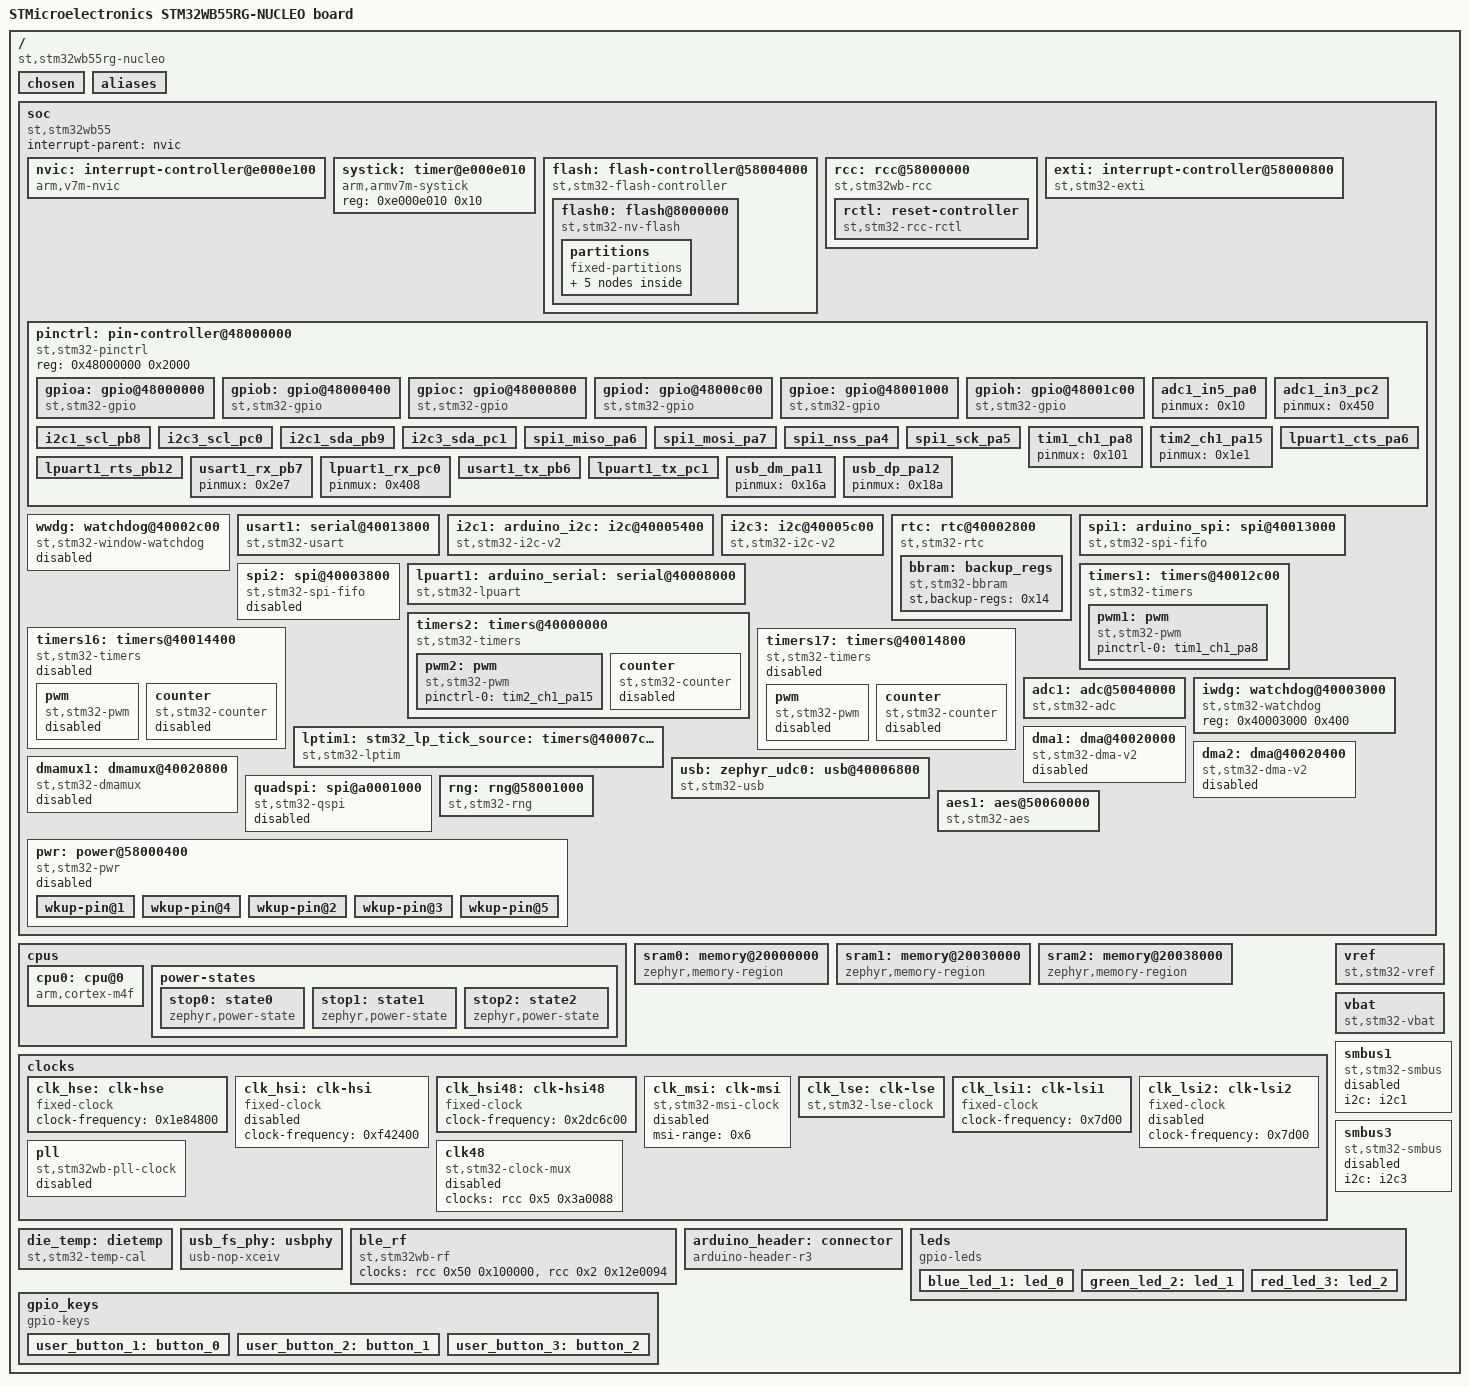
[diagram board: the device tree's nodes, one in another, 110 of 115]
/dts-v1/;

/* node '/' defined in zephyr/dts/common/skeleton.dtsi:9 */
/ {
	#address-cells = < 0x1 >;                              /* in zephyr/dts/common/skeleton.dtsi:10 */
	#size-cells = < 0x1 >;                                 /* in zephyr/dts/common/skeleton.dtsi:11 */
	model = "STMicroelectronics STM32WB55RG-NUCLEO board"; /* in zephyr/boards/st/nucleo_wb55rg/nucleo_wb55rg.dts:14 */
	compatible = "st,stm32wb55rg-nucleo";                  /* in zephyr/boards/st/nucleo_wb55rg/nucleo_wb55rg.dts:15 */

	/* node '/chosen' defined in zephyr/dts/common/skeleton.dtsi:13 */
	chosen {
		zephyr,entropy = &rng;                    /* in zephyr/dts/arm/st/wb/stm32wb.dtsi:25 */
		zephyr,flash-controller = &flash;         /* in zephyr/dts/arm/st/wb/stm32wb.dtsi:26 */
		zephyr,bt-hci = &ble_rf;                  /* in zephyr/dts/arm/st/wb/stm32wb.dtsi:27 */
		zephyr,console = &usart1;                 /* in zephyr/boards/st/nucleo_wb55rg/nucleo_wb55rg.dts:18 */
		zephyr,shell-uart = &usart1;              /* in zephyr/boards/st/nucleo_wb55rg/nucleo_wb55rg.dts:19 */
		zephyr,bt-mon-uart = &lpuart1;            /* in zephyr/boards/st/nucleo_wb55rg/nucleo_wb55rg.dts:20 */
		zephyr,bt-c2h-uart = &lpuart1;            /* in zephyr/boards/st/nucleo_wb55rg/nucleo_wb55rg.dts:21 */
		zephyr,sram = &sram0;                     /* in zephyr/boards/st/nucleo_wb55rg/nucleo_wb55rg.dts:22 */
		zephyr,flash = &flash0;                   /* in zephyr/boards/st/nucleo_wb55rg/nucleo_wb55rg.dts:23 */
		zephyr,code-partition = &slot0_partition; /* in zephyr/boards/st/nucleo_wb55rg/nucleo_wb55rg.dts:24 */
	};

	/* node '/aliases' defined in zephyr/dts/common/skeleton.dtsi:15 */
	aliases {
		led0 = &blue_led_1;               /* in zephyr/boards/st/nucleo_wb55rg/nucleo_wb55rg.dts:69 */
		led1 = &green_led_2;              /* in zephyr/boards/st/nucleo_wb55rg/nucleo_wb55rg.dts:70 */
		led2 = &red_led_3;                /* in zephyr/boards/st/nucleo_wb55rg/nucleo_wb55rg.dts:71 */
		sw0 = &user_button_1;             /* in zephyr/boards/st/nucleo_wb55rg/nucleo_wb55rg.dts:72 */
		sw1 = &user_button_2;             /* in zephyr/boards/st/nucleo_wb55rg/nucleo_wb55rg.dts:73 */
		sw2 = &user_button_3;             /* in zephyr/boards/st/nucleo_wb55rg/nucleo_wb55rg.dts:74 */
		watchdog0 = &iwdg;                /* in zephyr/boards/st/nucleo_wb55rg/nucleo_wb55rg.dts:75 */
		die-temp0 = &die_temp;            /* in zephyr/boards/st/nucleo_wb55rg/nucleo_wb55rg.dts:76 */
		volt-sensor0 = &vref;             /* in zephyr/boards/st/nucleo_wb55rg/nucleo_wb55rg.dts:77 */
		volt-sensor1 = &vbat;             /* in zephyr/boards/st/nucleo_wb55rg/nucleo_wb55rg.dts:78 */
		mcuboot-led0 = &blue_led_1;       /* in zephyr/boards/st/nucleo_wb55rg/nucleo_wb55rg.dts:79 */
		mcuboot-button0 = &user_button_1; /* in zephyr/boards/st/nucleo_wb55rg/nucleo_wb55rg.dts:80 */
	};

	/* node '/soc' defined in zephyr/dts/arm/armv7-m.dtsi:6 */
	soc {
		#address-cells = < 0x1 >;     /* in zephyr/dts/arm/armv7-m.dtsi:7 */
		#size-cells = < 0x1 >;        /* in zephyr/dts/arm/armv7-m.dtsi:8 */
		interrupt-parent = < &nvic >; /* in zephyr/dts/arm/armv7-m.dtsi:10 */
		ranges;                       /* in zephyr/dts/arm/armv7-m.dtsi:11 */
		compatible = "st,stm32wb55",
		             "st,stm32wb",
		             "simple-bus";    /* in zephyr/dts/arm/st/wb/stm32wb55.dtsi:11 */

		/* node '/soc/interrupt-controller@e000e100' defined in zephyr/dts/arm/armv7-m.dtsi:13 */
		nvic: interrupt-controller@e000e100 {
			#address-cells = < 0x1 >;            /* in zephyr/dts/arm/armv7-m.dtsi:14 */
			compatible = "arm,v7m-nvic";         /* in zephyr/dts/arm/armv7-m.dtsi:15 */
			reg = < 0xe000e100 0xc00 >;          /* in zephyr/dts/arm/armv7-m.dtsi:16 */
			interrupt-controller;                /* in zephyr/dts/arm/armv7-m.dtsi:17 */
			#interrupt-cells = < 0x2 >;          /* in zephyr/dts/arm/armv7-m.dtsi:18 */
			arm,num-irq-priority-bits = < 0x4 >; /* in zephyr/dts/arm/st/wb/stm32wb.dtsi:615 */
			phandle = < 0x1 >;                   /* in zephyr/dts/arm/armv7-m.dtsi:10 */
		};

		/* node '/soc/timer@e000e010' defined in zephyr/dts/arm/armv7-m.dtsi:21 */
		systick: timer@e000e010 {
			compatible = "arm,armv7m-systick"; /* in zephyr/dts/arm/armv7-m.dtsi:22 */
			reg = < 0xe000e010 0x10 >;         /* in zephyr/dts/arm/armv7-m.dtsi:23 */
		};

		/* node '/soc/flash-controller@58004000' defined in zephyr/dts/arm/st/wb/stm32wb.dtsi:148 */
		flash: flash-controller@58004000 {
			compatible = "st,stm32-flash-controller",
			             "st,stm32wb-flash-controller"; /* in zephyr/dts/arm/st/wb/stm32wb.dtsi:149 */
			reg = < 0x58004000 0x400 >;                 /* in zephyr/dts/arm/st/wb/stm32wb.dtsi:150 */
			interrupts = < 0x4 0x0 >;                   /* in zephyr/dts/arm/st/wb/stm32wb.dtsi:151 */
			clocks = < &rcc 0x50 0x2000000 >;           /* in zephyr/dts/arm/st/wb/stm32wb.dtsi:152 */
			#address-cells = < 0x1 >;                   /* in zephyr/dts/arm/st/wb/stm32wb.dtsi:154 */
			#size-cells = < 0x1 >;                      /* in zephyr/dts/arm/st/wb/stm32wb.dtsi:155 */

			/* node '/soc/flash-controller@58004000/flash@8000000' defined in zephyr/dts/arm/st/wb/stm32wb.dtsi:157 */
			flash0: flash@8000000 {
				compatible = "st,stm32-nv-flash",
				             "soc-nv-flash";      /* in zephyr/dts/arm/st/wb/stm32wb.dtsi:158 */
				write-block-size = < 0x8 >;       /* in zephyr/dts/arm/st/wb/stm32wb.dtsi:160 */
				erase-block-size = < 0x1000 >;    /* in zephyr/dts/arm/st/wb/stm32wb.dtsi:161 */
				max-erase-time = < 0x19 >;        /* in zephyr/dts/arm/st/wb/stm32wb.dtsi:163 */
				reg = < 0x8000000 0xca000 >;      /* in zephyr/dts/arm/st/wb/stm32wb55Xg.dtsi:17 */

				/* node '/soc/flash-controller@58004000/flash@8000000/partitions' defined in zephyr/boards/st/nucleo_wb55rg/nucleo_wb55rg.dts:221 */
				partitions {
					compatible = "fixed-partitions"; /* in zephyr/boards/st/nucleo_wb55rg/nucleo_wb55rg.dts:222 */
					#address-cells = < 0x1 >;        /* in zephyr/boards/st/nucleo_wb55rg/nucleo_wb55rg.dts:223 */
					#size-cells = < 0x1 >;           /* in zephyr/boards/st/nucleo_wb55rg/nucleo_wb55rg.dts:224 */

					/* node '/soc/flash-controller@58004000/flash@8000000/partitions/partition@0' defined in zephyr/boards/st/nucleo_wb55rg/nucleo_wb55rg.dts:233 */
					boot_partition: partition@0 {
						label = "mcuboot";    /* in zephyr/boards/st/nucleo_wb55rg/nucleo_wb55rg.dts:234 */
						reg = < 0x0 0xc000 >; /* in zephyr/boards/st/nucleo_wb55rg/nucleo_wb55rg.dts:235 */
					};

					/* node '/soc/flash-controller@58004000/flash@8000000/partitions/partition@c000' defined in zephyr/boards/st/nucleo_wb55rg/nucleo_wb55rg.dts:238 */
					slot0_partition: partition@c000 {
						label = "image-0";        /* in zephyr/boards/st/nucleo_wb55rg/nucleo_wb55rg.dts:239 */
						reg = < 0xc000 0x64000 >; /* in zephyr/boards/st/nucleo_wb55rg/nucleo_wb55rg.dts:240 */
					};

					/* node '/soc/flash-controller@58004000/flash@8000000/partitions/partition@70000' defined in zephyr/boards/st/nucleo_wb55rg/nucleo_wb55rg.dts:243 */
					slot1_partition: partition@70000 {
						label = "image-1";         /* in zephyr/boards/st/nucleo_wb55rg/nucleo_wb55rg.dts:244 */
						reg = < 0x70000 0x64000 >; /* in zephyr/boards/st/nucleo_wb55rg/nucleo_wb55rg.dts:245 */
					};

					/* node '/soc/flash-controller@58004000/flash@8000000/partitions/partition@d4000' defined in zephyr/boards/st/nucleo_wb55rg/nucleo_wb55rg.dts:248 */
					scratch_partition: partition@d4000 {
						label = "image-scratch";  /* in zephyr/boards/st/nucleo_wb55rg/nucleo_wb55rg.dts:249 */
						reg = < 0xd4000 0x4000 >; /* in zephyr/boards/st/nucleo_wb55rg/nucleo_wb55rg.dts:250 */
					};

					/* node '/soc/flash-controller@58004000/flash@8000000/partitions/partition@d8000' defined in zephyr/boards/st/nucleo_wb55rg/nucleo_wb55rg.dts:253 */
					storage_partition: partition@d8000 {
						label = "storage";        /* in zephyr/boards/st/nucleo_wb55rg/nucleo_wb55rg.dts:254 */
						reg = < 0xd8000 0x2000 >; /* in zephyr/boards/st/nucleo_wb55rg/nucleo_wb55rg.dts:255 */
					};
				};
			};
		};

		/* node '/soc/rcc@58000000' defined in zephyr/dts/arm/st/wb/stm32wb.dtsi:167 */
		rcc: rcc@58000000 {
			compatible = "st,stm32wb-rcc";   /* in zephyr/dts/arm/st/wb/stm32wb.dtsi:168 */
			#clock-cells = < 0x2 >;          /* in zephyr/dts/arm/st/wb/stm32wb.dtsi:169 */
			reg = < 0x58000000 0x400 >;      /* in zephyr/dts/arm/st/wb/stm32wb.dtsi:170 */
			clocks = < &clk_hse >;           /* in zephyr/boards/st/nucleo_wb55rg/nucleo_wb55rg.dts:111 */
			clock-frequency = < 0x1e84800 >; /* in zephyr/boards/st/nucleo_wb55rg/nucleo_wb55rg.dts:112 */
			cpu1-prescaler = < 0x1 >;        /* in zephyr/boards/st/nucleo_wb55rg/nucleo_wb55rg.dts:113 */
			cpu2-prescaler = < 0x1 >;        /* in zephyr/boards/st/nucleo_wb55rg/nucleo_wb55rg.dts:114 */
			ahb4-prescaler = < 0x1 >;        /* in zephyr/boards/st/nucleo_wb55rg/nucleo_wb55rg.dts:115 */
			apb1-prescaler = < 0x1 >;        /* in zephyr/boards/st/nucleo_wb55rg/nucleo_wb55rg.dts:116 */
			apb2-prescaler = < 0x1 >;        /* in zephyr/boards/st/nucleo_wb55rg/nucleo_wb55rg.dts:117 */
			phandle = < 0x2 >;               /* in zephyr/dts/arm/st/wb/stm32wb.dtsi:152 */

			/* node '/soc/rcc@58000000/reset-controller' defined in zephyr/dts/arm/st/wb/stm32wb.dtsi:172 */
			rctl: reset-controller {
				compatible = "st,stm32-rcc-rctl"; /* in zephyr/dts/arm/st/wb/stm32wb.dtsi:173 */
				#reset-cells = < 0x1 >;           /* in zephyr/dts/arm/st/wb/stm32wb.dtsi:174 */
				phandle = < 0x4 >;                /* in zephyr/dts/arm/st/wb/stm32wb.dtsi:262 */
			};
		};

		/* node '/soc/interrupt-controller@58000800' defined in zephyr/dts/arm/st/wb/stm32wb.dtsi:178 */
		exti: interrupt-controller@58000800 {
			compatible = "st,stm32-exti";  /* in zephyr/dts/arm/st/wb/stm32wb.dtsi:179 */
			interrupt-controller;          /* in zephyr/dts/arm/st/wb/stm32wb.dtsi:180 */
			#interrupt-cells = < 0x1 >;    /* in zephyr/dts/arm/st/wb/stm32wb.dtsi:181 */
			#address-cells = < 0x0 >;      /* in zephyr/dts/arm/st/wb/stm32wb.dtsi:182 */
			reg = < 0x58000800 0x400 >;    /* in zephyr/dts/arm/st/wb/stm32wb.dtsi:183 */
			num-lines = < 0x40 >;          /* in zephyr/dts/arm/st/wb/stm32wb.dtsi:184 */
			interrupts = < 0x6 0x0 >,
			             < 0x7 0x0 >,
			             < 0x8 0x0 >,
			             < 0x9 0x0 >,
			             < 0xa 0x0 >,
			             < 0x17 0x0 >,
			             < 0x28 0x0 >;     /* in zephyr/dts/arm/st/wb/stm32wb.dtsi:185 */
			interrupt-names = "line0",
			                  "line1",
			                  "line2",
			                  "line3",
			                  "line4",
			                  "line5-9",
			                  "line10-15"; /* in zephyr/dts/arm/st/wb/stm32wb.dtsi:187 */
			line-ranges = < 0x0 0x1 >,
			              < 0x1 0x1 >,
			              < 0x2 0x1 >,
			              < 0x3 0x1 >,
			              < 0x4 0x1 >,
			              < 0x5 0x5 >,
			              < 0xa 0x6 >;     /* in zephyr/dts/arm/st/wb/stm32wb.dtsi:189 */
		};

		/* node '/soc/pin-controller@48000000' defined in zephyr/dts/arm/st/wb/stm32wb.dtsi:193 */
		pinctrl: pin-controller@48000000 {
			compatible = "st,stm32-pinctrl"; /* in zephyr/dts/arm/st/wb/stm32wb.dtsi:194 */
			#address-cells = < 0x1 >;        /* in zephyr/dts/arm/st/wb/stm32wb.dtsi:195 */
			#size-cells = < 0x1 >;           /* in zephyr/dts/arm/st/wb/stm32wb.dtsi:196 */
			reg = < 0x48000000 0x2000 >;     /* in zephyr/dts/arm/st/wb/stm32wb.dtsi:197 */

			/* node '/soc/pin-controller@48000000/gpio@48000000' defined in zephyr/dts/arm/st/wb/stm32wb.dtsi:199 */
			gpioa: gpio@48000000 {
				compatible = "st,stm32-gpio"; /* in zephyr/dts/arm/st/wb/stm32wb.dtsi:200 */
				gpio-controller;              /* in zephyr/dts/arm/st/wb/stm32wb.dtsi:201 */
				#gpio-cells = < 0x2 >;        /* in zephyr/dts/arm/st/wb/stm32wb.dtsi:202 */
				reg = < 0x48000000 0x400 >;   /* in zephyr/dts/arm/st/wb/stm32wb.dtsi:203 */
				clocks = < &rcc 0x4c 0x1 >;   /* in zephyr/dts/arm/st/wb/stm32wb.dtsi:204 */
				phandle = < 0x1a >;           /* in zephyr/dts/arm/st/wb/stm32wb.dtsi:550 */
			};

			/* node '/soc/pin-controller@48000000/gpio@48000400' defined in zephyr/dts/arm/st/wb/stm32wb.dtsi:207 */
			gpiob: gpio@48000400 {
				compatible = "st,stm32-gpio"; /* in zephyr/dts/arm/st/wb/stm32wb.dtsi:208 */
				gpio-controller;              /* in zephyr/dts/arm/st/wb/stm32wb.dtsi:209 */
				#gpio-cells = < 0x2 >;        /* in zephyr/dts/arm/st/wb/stm32wb.dtsi:210 */
				reg = < 0x48000400 0x400 >;   /* in zephyr/dts/arm/st/wb/stm32wb.dtsi:211 */
				clocks = < &rcc 0x4c 0x2 >;   /* in zephyr/dts/arm/st/wb/stm32wb.dtsi:212 */
				phandle = < 0x22 >;           /* in zephyr/boards/st/nucleo_wb55rg/arduino_r3_connector.dtsi:15 */
			};

			/* node '/soc/pin-controller@48000000/gpio@48000800' defined in zephyr/dts/arm/st/wb/stm32wb.dtsi:215 */
			gpioc: gpio@48000800 {
				compatible = "st,stm32-gpio"; /* in zephyr/dts/arm/st/wb/stm32wb.dtsi:216 */
				gpio-controller;              /* in zephyr/dts/arm/st/wb/stm32wb.dtsi:217 */
				#gpio-cells = < 0x2 >;        /* in zephyr/dts/arm/st/wb/stm32wb.dtsi:218 */
				reg = < 0x48000800 0x400 >;   /* in zephyr/dts/arm/st/wb/stm32wb.dtsi:219 */
				clocks = < &rcc 0x4c 0x4 >;   /* in zephyr/dts/arm/st/wb/stm32wb.dtsi:220 */
				phandle = < 0x1b >;           /* in zephyr/dts/arm/st/wb/stm32wb55Xg.dtsi:26 */
			};

			/* node '/soc/pin-controller@48000000/gpio@48000c00' defined in zephyr/dts/arm/st/wb/stm32wb.dtsi:223 */
			gpiod: gpio@48000c00 {
				compatible = "st,stm32-gpio"; /* in zephyr/dts/arm/st/wb/stm32wb.dtsi:224 */
				gpio-controller;              /* in zephyr/dts/arm/st/wb/stm32wb.dtsi:225 */
				#gpio-cells = < 0x2 >;        /* in zephyr/dts/arm/st/wb/stm32wb.dtsi:226 */
				reg = < 0x48000c00 0x400 >;   /* in zephyr/dts/arm/st/wb/stm32wb.dtsi:227 */
				clocks = < &rcc 0x4c 0x8 >;   /* in zephyr/dts/arm/st/wb/stm32wb.dtsi:228 */
				phandle = < 0x23 >;           /* in zephyr/boards/st/nucleo_wb55rg/nucleo_wb55rg.dts:57 */
			};

			/* node '/soc/pin-controller@48000000/gpio@48001000' defined in zephyr/dts/arm/st/wb/stm32wb.dtsi:231 */
			gpioe: gpio@48001000 {
				compatible = "st,stm32-gpio"; /* in zephyr/dts/arm/st/wb/stm32wb.dtsi:232 */
				gpio-controller;              /* in zephyr/dts/arm/st/wb/stm32wb.dtsi:233 */
				#gpio-cells = < 0x2 >;        /* in zephyr/dts/arm/st/wb/stm32wb.dtsi:234 */
				ngpios = < 0x5 >;             /* in zephyr/dts/arm/st/wb/stm32wb.dtsi:235 */
				reg = < 0x48001000 0x400 >;   /* in zephyr/dts/arm/st/wb/stm32wb.dtsi:236 */
				clocks = < &rcc 0x4c 0x10 >;  /* in zephyr/dts/arm/st/wb/stm32wb.dtsi:237 */
			};

			/* node '/soc/pin-controller@48000000/gpio@48001c00' defined in zephyr/dts/arm/st/wb/stm32wb.dtsi:240 */
			gpioh: gpio@48001c00 {
				compatible = "st,stm32-gpio"; /* in zephyr/dts/arm/st/wb/stm32wb.dtsi:241 */
				gpio-controller;              /* in zephyr/dts/arm/st/wb/stm32wb.dtsi:242 */
				#gpio-cells = < 0x2 >;        /* in zephyr/dts/arm/st/wb/stm32wb.dtsi:243 */
				ngpios = < 0x4 >;             /* in zephyr/dts/arm/st/wb/stm32wb.dtsi:244 */
				reg = < 0x48001c00 0x400 >;   /* in zephyr/dts/arm/st/wb/stm32wb.dtsi:245 */
				clocks = < &rcc 0x4c 0x80 >;  /* in zephyr/dts/arm/st/wb/stm32wb.dtsi:246 */
			};

			/* node '/soc/pin-controller@48000000/adc1_in5_pa0' defined in modules/hal/stm32/dts/st/wb/stm32wb55rgvx-pinctrl.dtsi:15 */
			adc1_in5_pa0: adc1_in5_pa0 {
				pinmux = < 0x10 >;  /* in modules/hal/stm32/dts/st/wb/stm32wb55rgvx-pinctrl.dtsi:16 */
				phandle = < 0x16 >; /* in zephyr/boards/st/nucleo_wb55rg/nucleo_wb55rg.dts:189 */
			};

			/* node '/soc/pin-controller@48000000/adc1_in3_pc2' defined in modules/hal/stm32/dts/st/wb/stm32wb55rgvx-pinctrl.dtsi:63 */
			adc1_in3_pc2: adc1_in3_pc2 {
				pinmux = < 0x450 >; /* in modules/hal/stm32/dts/st/wb/stm32wb55rgvx-pinctrl.dtsi:64 */
				phandle = < 0x15 >; /* in zephyr/boards/st/nucleo_wb55rg/nucleo_wb55rg.dts:189 */
			};

			/* node '/soc/pin-controller@48000000/i2c1_scl_pb8' defined in modules/hal/stm32/dts/st/wb/stm32wb55rgvx-pinctrl.dtsi:387 */
			i2c1_scl_pb8: i2c1_scl_pb8 {
				pinmux = < 0x304 >; /* in modules/hal/stm32/dts/st/wb/stm32wb55rgvx-pinctrl.dtsi:388 */
				bias-pull-up;       /* in modules/hal/stm32/dts/st/wb/stm32wb55rgvx-pinctrl.dtsi:389 */
				drive-open-drain;   /* in modules/hal/stm32/dts/st/wb/stm32wb55rgvx-pinctrl.dtsi:390 */
				phandle = < 0x7 >;  /* in zephyr/boards/st/nucleo_wb55rg/nucleo_wb55rg.dts:128 */
			};

			/* node '/soc/pin-controller@48000000/i2c3_scl_pc0' defined in modules/hal/stm32/dts/st/wb/stm32wb55rgvx-pinctrl.dtsi:411 */
			i2c3_scl_pc0: i2c3_scl_pc0 {
				pinmux = < 0x404 >; /* in modules/hal/stm32/dts/st/wb/stm32wb55rgvx-pinctrl.dtsi:412 */
				bias-pull-up;       /* in modules/hal/stm32/dts/st/wb/stm32wb55rgvx-pinctrl.dtsi:413 */
				drive-open-drain;   /* in modules/hal/stm32/dts/st/wb/stm32wb55rgvx-pinctrl.dtsi:414 */
				phandle = < 0x9 >;  /* in zephyr/boards/st/nucleo_wb55rg/nucleo_wb55rg.dts:135 */
			};

			/* node '/soc/pin-controller@48000000/i2c1_sda_pb9' defined in modules/hal/stm32/dts/st/wb/stm32wb55rgvx-pinctrl.dtsi:431 */
			i2c1_sda_pb9: i2c1_sda_pb9 {
				pinmux = < 0x324 >; /* in modules/hal/stm32/dts/st/wb/stm32wb55rgvx-pinctrl.dtsi:432 */
				bias-pull-up;       /* in modules/hal/stm32/dts/st/wb/stm32wb55rgvx-pinctrl.dtsi:433 */
				drive-open-drain;   /* in modules/hal/stm32/dts/st/wb/stm32wb55rgvx-pinctrl.dtsi:434 */
				phandle = < 0x8 >;  /* in zephyr/boards/st/nucleo_wb55rg/nucleo_wb55rg.dts:128 */
			};

			/* node '/soc/pin-controller@48000000/i2c3_sda_pc1' defined in modules/hal/stm32/dts/st/wb/stm32wb55rgvx-pinctrl.dtsi:455 */
			i2c3_sda_pc1: i2c3_sda_pc1 {
				pinmux = < 0x424 >; /* in modules/hal/stm32/dts/st/wb/stm32wb55rgvx-pinctrl.dtsi:456 */
				bias-pull-up;       /* in modules/hal/stm32/dts/st/wb/stm32wb55rgvx-pinctrl.dtsi:457 */
				drive-open-drain;   /* in modules/hal/stm32/dts/st/wb/stm32wb55rgvx-pinctrl.dtsi:458 */
				phandle = < 0xa >;  /* in zephyr/boards/st/nucleo_wb55rg/nucleo_wb55rg.dts:135 */
			};

			/* node '/soc/pin-controller@48000000/spi1_miso_pa6' defined in modules/hal/stm32/dts/st/wb/stm32wb55rgvx-pinctrl.dtsi:693 */
			spi1_miso_pa6: spi1_miso_pa6 {
				pinmux = < 0xc5 >; /* in modules/hal/stm32/dts/st/wb/stm32wb55rgvx-pinctrl.dtsi:694 */
				bias-pull-down;    /* in modules/hal/stm32/dts/st/wb/stm32wb55rgvx-pinctrl.dtsi:695 */
				phandle = < 0xd >; /* in zephyr/boards/st/nucleo_wb55rg/nucleo_wb55rg.dts:152 */
			};

			/* node '/soc/pin-controller@48000000/spi1_mosi_pa7' defined in modules/hal/stm32/dts/st/wb/stm32wb55rgvx-pinctrl.dtsi:720 */
			spi1_mosi_pa7: spi1_mosi_pa7 {
				pinmux = < 0xe5 >; /* in modules/hal/stm32/dts/st/wb/stm32wb55rgvx-pinctrl.dtsi:721 */
				bias-pull-down;    /* in modules/hal/stm32/dts/st/wb/stm32wb55rgvx-pinctrl.dtsi:722 */
				phandle = < 0xe >; /* in zephyr/boards/st/nucleo_wb55rg/nucleo_wb55rg.dts:152 */
			};

			/* node '/soc/pin-controller@48000000/spi1_nss_pa4' defined in modules/hal/stm32/dts/st/wb/stm32wb55rgvx-pinctrl.dtsi:752 */
			spi1_nss_pa4: spi1_nss_pa4 {
				pinmux = < 0x85 >; /* in modules/hal/stm32/dts/st/wb/stm32wb55rgvx-pinctrl.dtsi:753 */
				bias-pull-up;      /* in modules/hal/stm32/dts/st/wb/stm32wb55rgvx-pinctrl.dtsi:754 */
				phandle = < 0xb >; /* in zephyr/boards/st/nucleo_wb55rg/nucleo_wb55rg.dts:152 */
			};

			/* node '/soc/pin-controller@48000000/spi1_sck_pa5' defined in modules/hal/stm32/dts/st/wb/stm32wb55rgvx-pinctrl.dtsi:790 */
			spi1_sck_pa5: spi1_sck_pa5 {
				pinmux = < 0xa5 >;             /* in modules/hal/stm32/dts/st/wb/stm32wb55rgvx-pinctrl.dtsi:791 */
				bias-pull-down;                /* in modules/hal/stm32/dts/st/wb/stm32wb55rgvx-pinctrl.dtsi:792 */
				slew-rate = "very-high-speed"; /* in modules/hal/stm32/dts/st/wb/stm32wb55rgvx-pinctrl.dtsi:793 */
				phandle = < 0xc >;             /* in zephyr/boards/st/nucleo_wb55rg/nucleo_wb55rg.dts:152 */
			};

			/* node '/soc/pin-controller@48000000/tim1_ch1_pa8' defined in modules/hal/stm32/dts/st/wb/stm32wb55rgvx-pinctrl.dtsi:862 */
			tim1_ch1_pa8: tim1_ch1_pa8 {
				pinmux = < 0x101 >; /* in modules/hal/stm32/dts/st/wb/stm32wb55rgvx-pinctrl.dtsi:863 */
				phandle = < 0x13 >; /* in zephyr/boards/st/nucleo_wb55rg/nucleo_wb55rg.dts:164 */
			};

			/* node '/soc/pin-controller@48000000/tim2_ch1_pa15' defined in modules/hal/stm32/dts/st/wb/stm32wb55rgvx-pinctrl.dtsi:918 */
			tim2_ch1_pa15: tim2_ch1_pa15 {
				pinmux = < 0x1e1 >; /* in modules/hal/stm32/dts/st/wb/stm32wb55rgvx-pinctrl.dtsi:919 */
				phandle = < 0x14 >; /* in zephyr/boards/st/nucleo_wb55rg/nucleo_wb55rg.dts:174 */
			};

			/* node '/soc/pin-controller@48000000/lpuart1_cts_pa6' defined in modules/hal/stm32/dts/st/wb/stm32wb55rgvx-pinctrl.dtsi:1014 */
			lpuart1_cts_pa6: lpuart1_cts_pa6 {
				pinmux = < 0xc8 >;  /* in modules/hal/stm32/dts/st/wb/stm32wb55rgvx-pinctrl.dtsi:1015 */
				bias-pull-up;       /* in modules/hal/stm32/dts/st/wb/stm32wb55rgvx-pinctrl.dtsi:1016 */
				phandle = < 0x11 >; /* in zephyr/boards/st/nucleo_wb55rg/nucleo_wb55rg.dts:180 */
			};

			/* node '/soc/pin-controller@48000000/lpuart1_rts_pb12' defined in modules/hal/stm32/dts/st/wb/stm32wb55rgvx-pinctrl.dtsi:1073 */
			lpuart1_rts_pb12: lpuart1_rts_pb12 {
				pinmux = < 0x388 >; /* in modules/hal/stm32/dts/st/wb/stm32wb55rgvx-pinctrl.dtsi:1074 */
				drive-push-pull;    /* in modules/hal/stm32/dts/st/wb/stm32wb55rgvx-pinctrl.dtsi:1075 */
				phandle = < 0x12 >; /* in zephyr/boards/st/nucleo_wb55rg/nucleo_wb55rg.dts:180 */
			};

			/* node '/soc/pin-controller@48000000/usart1_rx_pb7' defined in modules/hal/stm32/dts/st/wb/stm32wb55rgvx-pinctrl.dtsi:1092 */
			usart1_rx_pb7: usart1_rx_pb7 {
				pinmux = < 0x2e7 >; /* in modules/hal/stm32/dts/st/wb/stm32wb55rgvx-pinctrl.dtsi:1093 */
				phandle = < 0x6 >;  /* in zephyr/boards/st/nucleo_wb55rg/nucleo_wb55rg.dts:121 */
			};

			/* node '/soc/pin-controller@48000000/lpuart1_rx_pc0' defined in modules/hal/stm32/dts/st/wb/stm32wb55rgvx-pinctrl.dtsi:1100 */
			lpuart1_rx_pc0: lpuart1_rx_pc0 {
				pinmux = < 0x408 >; /* in modules/hal/stm32/dts/st/wb/stm32wb55rgvx-pinctrl.dtsi:1101 */
				phandle = < 0x10 >; /* in zephyr/boards/st/nucleo_wb55rg/nucleo_wb55rg.dts:180 */
			};

			/* node '/soc/pin-controller@48000000/usart1_tx_pb6' defined in modules/hal/stm32/dts/st/wb/stm32wb55rgvx-pinctrl.dtsi:1121 */
			usart1_tx_pb6: usart1_tx_pb6 {
				pinmux = < 0x2c7 >; /* in modules/hal/stm32/dts/st/wb/stm32wb55rgvx-pinctrl.dtsi:1122 */
				bias-pull-up;       /* in modules/hal/stm32/dts/st/wb/stm32wb55rgvx-pinctrl.dtsi:1123 */
				phandle = < 0x5 >;  /* in zephyr/boards/st/nucleo_wb55rg/nucleo_wb55rg.dts:121 */
			};

			/* node '/soc/pin-controller@48000000/lpuart1_tx_pc1' defined in modules/hal/stm32/dts/st/wb/stm32wb55rgvx-pinctrl.dtsi:1131 */
			lpuart1_tx_pc1: lpuart1_tx_pc1 {
				pinmux = < 0x428 >; /* in modules/hal/stm32/dts/st/wb/stm32wb55rgvx-pinctrl.dtsi:1132 */
				bias-pull-up;       /* in modules/hal/stm32/dts/st/wb/stm32wb55rgvx-pinctrl.dtsi:1133 */
				phandle = < 0xf >;  /* in zephyr/boards/st/nucleo_wb55rg/nucleo_wb55rg.dts:180 */
			};

			/* node '/soc/pin-controller@48000000/usb_dm_pa11' defined in modules/hal/stm32/dts/st/wb/stm32wb55rgvx-pinctrl.dtsi:1138 */
			usb_dm_pa11: usb_dm_pa11 {
				pinmux = < 0x16a >; /* in modules/hal/stm32/dts/st/wb/stm32wb55rgvx-pinctrl.dtsi:1139 */
				phandle = < 0x18 >; /* in zephyr/boards/st/nucleo_wb55rg/nucleo_wb55rg.dts:208 */
			};

			/* node '/soc/pin-controller@48000000/usb_dp_pa12' defined in modules/hal/stm32/dts/st/wb/stm32wb55rgvx-pinctrl.dtsi:1142 */
			usb_dp_pa12: usb_dp_pa12 {
				pinmux = < 0x18a >; /* in modules/hal/stm32/dts/st/wb/stm32wb55rgvx-pinctrl.dtsi:1143 */
				phandle = < 0x19 >; /* in zephyr/boards/st/nucleo_wb55rg/nucleo_wb55rg.dts:208 */
			};
		};

		/* node '/soc/watchdog@40002c00' defined in zephyr/dts/arm/st/wb/stm32wb.dtsi:250 */
		wwdg: watchdog@40002c00 {
			compatible = "st,stm32-window-watchdog"; /* in zephyr/dts/arm/st/wb/stm32wb.dtsi:251 */
			reg = < 0x40002c00 0x400 >;              /* in zephyr/dts/arm/st/wb/stm32wb.dtsi:252 */
			clocks = < &rcc 0x58 0x800 >;            /* in zephyr/dts/arm/st/wb/stm32wb.dtsi:253 */
			interrupts = < 0x0 0x7 >;                /* in zephyr/dts/arm/st/wb/stm32wb.dtsi:254 */
			status = "disabled";                     /* in zephyr/dts/arm/st/wb/stm32wb.dtsi:255 */
		};

		/* node '/soc/serial@40013800' defined in zephyr/dts/arm/st/wb/stm32wb.dtsi:258 */
		usart1: serial@40013800 {
			compatible = "st,stm32-usart",
			             "st,stm32-uart";                  /* in zephyr/dts/arm/st/wb/stm32wb.dtsi:259 */
			reg = < 0x40013800 0x400 >;                    /* in zephyr/dts/arm/st/wb/stm32wb.dtsi:260 */
			clocks = < &rcc 0x60 0x4000 >;                 /* in zephyr/dts/arm/st/wb/stm32wb.dtsi:261 */
			resets = < &rctl 0x80e >;                      /* in zephyr/dts/arm/st/wb/stm32wb.dtsi:262 */
			interrupts = < 0x24 0x0 >;                     /* in zephyr/dts/arm/st/wb/stm32wb.dtsi:263 */
			pinctrl-0 = < &usart1_tx_pb6 &usart1_rx_pb7 >; /* in zephyr/boards/st/nucleo_wb55rg/nucleo_wb55rg.dts:121 */
			pinctrl-names = "default";                     /* in zephyr/boards/st/nucleo_wb55rg/nucleo_wb55rg.dts:122 */
			current-speed = < 0x1c200 >;                   /* in zephyr/boards/st/nucleo_wb55rg/nucleo_wb55rg.dts:123 */
			status = "okay";                               /* in zephyr/boards/st/nucleo_wb55rg/nucleo_wb55rg.dts:124 */
		};

		/* node '/soc/i2c@40005400' defined in zephyr/dts/arm/st/wb/stm32wb.dtsi:267 */
		i2c1: arduino_i2c: i2c@40005400 {
			compatible = "st,stm32-i2c-v2";              /* in zephyr/dts/arm/st/wb/stm32wb.dtsi:268 */
			#address-cells = < 0x1 >;                    /* in zephyr/dts/arm/st/wb/stm32wb.dtsi:270 */
			#size-cells = < 0x0 >;                       /* in zephyr/dts/arm/st/wb/stm32wb.dtsi:271 */
			reg = < 0x40005400 0x400 >;                  /* in zephyr/dts/arm/st/wb/stm32wb.dtsi:272 */
			clocks = < &rcc 0x58 0x200000 >;             /* in zephyr/dts/arm/st/wb/stm32wb.dtsi:273 */
			interrupts = < 0x1e 0x0 >,
			             < 0x1f 0x0 >;                   /* in zephyr/dts/arm/st/wb/stm32wb.dtsi:274 */
			interrupt-names = "event",
			                  "error";                   /* in zephyr/dts/arm/st/wb/stm32wb.dtsi:275 */
			pinctrl-0 = < &i2c1_scl_pb8 &i2c1_sda_pb9 >; /* in zephyr/boards/st/nucleo_wb55rg/nucleo_wb55rg.dts:128 */
			pinctrl-names = "default";                   /* in zephyr/boards/st/nucleo_wb55rg/nucleo_wb55rg.dts:129 */
			status = "okay";                             /* in zephyr/boards/st/nucleo_wb55rg/nucleo_wb55rg.dts:130 */
			clock-frequency = < 0x61a80 >;               /* in zephyr/boards/st/nucleo_wb55rg/nucleo_wb55rg.dts:131 */
			phandle = < 0x20 >;                          /* in zephyr/dts/arm/st/wb/stm32wb.dtsi:601 */
		};

		/* node '/soc/i2c@40005c00' defined in zephyr/dts/arm/st/wb/stm32wb.dtsi:279 */
		i2c3: i2c@40005c00 {
			compatible = "st,stm32-i2c-v2";              /* in zephyr/dts/arm/st/wb/stm32wb.dtsi:280 */
			#address-cells = < 0x1 >;                    /* in zephyr/dts/arm/st/wb/stm32wb.dtsi:282 */
			#size-cells = < 0x0 >;                       /* in zephyr/dts/arm/st/wb/stm32wb.dtsi:283 */
			reg = < 0x40005c00 0x400 >;                  /* in zephyr/dts/arm/st/wb/stm32wb.dtsi:284 */
			clocks = < &rcc 0x58 0x800000 >;             /* in zephyr/dts/arm/st/wb/stm32wb.dtsi:285 */
			interrupts = < 0x20 0x0 >,
			             < 0x21 0x0 >;                   /* in zephyr/dts/arm/st/wb/stm32wb.dtsi:286 */
			interrupt-names = "event",
			                  "error";                   /* in zephyr/dts/arm/st/wb/stm32wb.dtsi:287 */
			pinctrl-0 = < &i2c3_scl_pc0 &i2c3_sda_pc1 >; /* in zephyr/boards/st/nucleo_wb55rg/nucleo_wb55rg.dts:135 */
			pinctrl-names = "default";                   /* in zephyr/boards/st/nucleo_wb55rg/nucleo_wb55rg.dts:136 */
			status = "okay";                             /* in zephyr/boards/st/nucleo_wb55rg/nucleo_wb55rg.dts:137 */
			clock-frequency = < 0x61a80 >;               /* in zephyr/boards/st/nucleo_wb55rg/nucleo_wb55rg.dts:138 */
			phandle = < 0x21 >;                          /* in zephyr/dts/arm/st/wb/stm32wb.dtsi:609 */
		};

		/* node '/soc/rtc@40002800' defined in zephyr/dts/arm/st/wb/stm32wb.dtsi:291 */
		rtc: rtc@40002800 {
			compatible = "st,stm32-rtc";     /* in zephyr/dts/arm/st/wb/stm32wb.dtsi:292 */
			reg = < 0x40002800 0x400 >;      /* in zephyr/dts/arm/st/wb/stm32wb.dtsi:293 */
			interrupts = < 0x29 0x0 >;       /* in zephyr/dts/arm/st/wb/stm32wb.dtsi:294 */
			prescaler = < 0x8000 >;          /* in zephyr/dts/arm/st/wb/stm32wb.dtsi:296 */
			alarms-count = < 0x2 >;          /* in zephyr/dts/arm/st/wb/stm32wb.dtsi:297 */
			alrm-exti-line = < 0x11 >;       /* in zephyr/dts/arm/st/wb/stm32wb.dtsi:298 */
			clocks = < &rcc 0x58 0x400 >,
			         < &rcc 0x3 0x2280090 >; /* in zephyr/boards/st/nucleo_wb55rg/nucleo_wb55rg.dts:142 */
			status = "okay";                 /* in zephyr/boards/st/nucleo_wb55rg/nucleo_wb55rg.dts:144 */

			/* node '/soc/rtc@40002800/backup_regs' defined in zephyr/dts/arm/st/wb/stm32wb.dtsi:301 */
			bbram: backup_regs {
				compatible = "st,stm32-bbram"; /* in zephyr/dts/arm/st/wb/stm32wb.dtsi:302 */
				st,backup-regs = < 0x14 >;     /* in zephyr/dts/arm/st/wb/stm32wb.dtsi:303 */
				status = "okay";               /* in zephyr/boards/st/nucleo_wb55rg/nucleo_wb55rg.dts:147 */
			};
		};

		/* node '/soc/spi@40013000' defined in zephyr/dts/arm/st/wb/stm32wb.dtsi:308 */
		spi1: arduino_spi: spi@40013000 {
			compatible = "st,stm32-spi-fifo",
			             "st,stm32-spi";                                               /* in zephyr/dts/arm/st/wb/stm32wb.dtsi:309 */
			#address-cells = < 0x1 >;                                                  /* in zephyr/dts/arm/st/wb/stm32wb.dtsi:310 */
			#size-cells = < 0x0 >;                                                     /* in zephyr/dts/arm/st/wb/stm32wb.dtsi:311 */
			reg = < 0x40013000 0x400 >;                                                /* in zephyr/dts/arm/st/wb/stm32wb.dtsi:312 */
			interrupts = < 0x22 0x5 >;                                                 /* in zephyr/dts/arm/st/wb/stm32wb.dtsi:313 */
			clocks = < &rcc 0x60 0x1000 >;                                             /* in zephyr/dts/arm/st/wb/stm32wb.dtsi:314 */
			pinctrl-0 = < &spi1_nss_pa4 &spi1_sck_pa5 &spi1_miso_pa6 &spi1_mosi_pa7 >; /* in zephyr/boards/st/nucleo_wb55rg/nucleo_wb55rg.dts:152 */
			pinctrl-names = "default";                                                 /* in zephyr/boards/st/nucleo_wb55rg/nucleo_wb55rg.dts:154 */
			status = "okay";                                                           /* in zephyr/boards/st/nucleo_wb55rg/nucleo_wb55rg.dts:155 */
		};

		/* node '/soc/spi@40003800' defined in zephyr/dts/arm/st/wb/stm32wb.dtsi:318 */
		spi2: spi@40003800 {
			compatible = "st,stm32-spi-fifo",
			             "st,stm32-spi";      /* in zephyr/dts/arm/st/wb/stm32wb.dtsi:319 */
			#address-cells = < 0x1 >;         /* in zephyr/dts/arm/st/wb/stm32wb.dtsi:320 */
			#size-cells = < 0x0 >;            /* in zephyr/dts/arm/st/wb/stm32wb.dtsi:321 */
			reg = < 0x40003800 0x400 >;       /* in zephyr/dts/arm/st/wb/stm32wb.dtsi:322 */
			interrupts = < 0x23 0x5 >;        /* in zephyr/dts/arm/st/wb/stm32wb.dtsi:323 */
			clocks = < &rcc 0x58 0x4000 >;    /* in zephyr/dts/arm/st/wb/stm32wb.dtsi:324 */
			status = "disabled";              /* in zephyr/dts/arm/st/wb/stm32wb.dtsi:325 */
		};

		/* node '/soc/serial@40008000' defined in zephyr/dts/arm/st/wb/stm32wb.dtsi:328 */
		lpuart1: arduino_serial: serial@40008000 {
			compatible = "st,stm32-lpuart",
			             "st,stm32-uart";                                                       /* in zephyr/dts/arm/st/wb/stm32wb.dtsi:329 */
			reg = < 0x40008000 0x400 >;                                                         /* in zephyr/dts/arm/st/wb/stm32wb.dtsi:330 */
			clocks = < &rcc 0x5c 0x1 >;                                                         /* in zephyr/dts/arm/st/wb/stm32wb.dtsi:331 */
			resets = < &rctl 0x780 >;                                                           /* in zephyr/dts/arm/st/wb/stm32wb.dtsi:332 */
			interrupts = < 0x25 0x0 >;                                                          /* in zephyr/dts/arm/st/wb/stm32wb.dtsi:333 */
			pinctrl-0 = < &lpuart1_tx_pc1 &lpuart1_rx_pc0 &lpuart1_cts_pa6 &lpuart1_rts_pb12 >; /* in zephyr/boards/st/nucleo_wb55rg/nucleo_wb55rg.dts:180 */
			hw-flow-control;                                                                    /* in zephyr/boards/st/nucleo_wb55rg/nucleo_wb55rg.dts:182 */
			pinctrl-names = "default";                                                          /* in zephyr/boards/st/nucleo_wb55rg/nucleo_wb55rg.dts:183 */
			current-speed = < 0x1c200 >;                                                        /* in zephyr/boards/st/nucleo_wb55rg/nucleo_wb55rg.dts:184 */
			status = "okay";                                                                    /* in zephyr/boards/st/nucleo_wb55rg/nucleo_wb55rg.dts:185 */
		};

		/* node '/soc/timers@40012c00' defined in zephyr/dts/arm/st/wb/stm32wb.dtsi:337 */
		timers1: timers@40012c00 {
			compatible = "st,stm32-timers"; /* in zephyr/dts/arm/st/wb/stm32wb.dtsi:338 */
			reg = < 0x40012c00 0x400 >;     /* in zephyr/dts/arm/st/wb/stm32wb.dtsi:339 */
			clocks = < &rcc 0x60 0x800 >,
			         < &rcc 0xa 0xff >;     /* in zephyr/dts/arm/st/wb/stm32wb.dtsi:340 */
			resets = < &rctl 0x80b >;       /* in zephyr/dts/arm/st/wb/stm32wb.dtsi:342 */
			interrupts = < 0x18 0x0 >,
			             < 0x19 0x0 >,
			             < 0x1a 0x0 >,
			             < 0x1b 0x0 >;      /* in zephyr/dts/arm/st/wb/stm32wb.dtsi:343 */
			interrupt-names = "brk",
			                  "up",
			                  "trgcom",
			                  "cc";         /* in zephyr/dts/arm/st/wb/stm32wb.dtsi:344 */
			st,prescaler = < 0x2710 >;      /* in zephyr/boards/st/nucleo_wb55rg/nucleo_wb55rg.dts:159 */
			status = "okay";                /* in zephyr/boards/st/nucleo_wb55rg/nucleo_wb55rg.dts:160 */

			/* node '/soc/timers@40012c00/pwm' defined in zephyr/dts/arm/st/wb/stm32wb.dtsi:348 */
			pwm1: pwm {
				compatible = "st,stm32-pwm";   /* in zephyr/dts/arm/st/wb/stm32wb.dtsi:349 */
				#pwm-cells = < 0x3 >;          /* in zephyr/dts/arm/st/wb/stm32wb.dtsi:351 */
				status = "okay";               /* in zephyr/boards/st/nucleo_wb55rg/nucleo_wb55rg.dts:163 */
				pinctrl-0 = < &tim1_ch1_pa8 >; /* in zephyr/boards/st/nucleo_wb55rg/nucleo_wb55rg.dts:164 */
				pinctrl-names = "default";     /* in zephyr/boards/st/nucleo_wb55rg/nucleo_wb55rg.dts:165 */
			};
		};

		/* node '/soc/timers@40000000' defined in zephyr/dts/arm/st/wb/stm32wb.dtsi:355 */
		timers2: timers@40000000 {
			compatible = "st,stm32-timers"; /* in zephyr/dts/arm/st/wb/stm32wb.dtsi:356 */
			reg = < 0x40000000 0x400 >;     /* in zephyr/dts/arm/st/wb/stm32wb.dtsi:357 */
			clocks = < &rcc 0x58 0x1 >,
			         < &rcc 0x9 0xff >;     /* in zephyr/dts/arm/st/wb/stm32wb.dtsi:358 */
			resets = < &rctl 0x700 >;       /* in zephyr/dts/arm/st/wb/stm32wb.dtsi:360 */
			interrupts = < 0x1c 0x0 >;      /* in zephyr/dts/arm/st/wb/stm32wb.dtsi:361 */
			interrupt-names = "global";     /* in zephyr/dts/arm/st/wb/stm32wb.dtsi:362 */
			st,prescaler = < 0x0 >;         /* in zephyr/dts/arm/st/wb/stm32wb.dtsi:363 */
			status = "okay";                /* in zephyr/boards/st/nucleo_wb55rg/nucleo_wb55rg.dts:170 */

			/* node '/soc/timers@40000000/pwm' defined in zephyr/dts/arm/st/wb/stm32wb.dtsi:366 */
			pwm2: pwm {
				compatible = "st,stm32-pwm";    /* in zephyr/dts/arm/st/wb/stm32wb.dtsi:367 */
				#pwm-cells = < 0x3 >;           /* in zephyr/dts/arm/st/wb/stm32wb.dtsi:369 */
				status = "okay";                /* in zephyr/boards/st/nucleo_wb55rg/nucleo_wb55rg.dts:173 */
				pinctrl-0 = < &tim2_ch1_pa15 >; /* in zephyr/boards/st/nucleo_wb55rg/nucleo_wb55rg.dts:174 */
				pinctrl-names = "default";      /* in zephyr/boards/st/nucleo_wb55rg/nucleo_wb55rg.dts:175 */
			};

			/* node '/soc/timers@40000000/counter' defined in zephyr/dts/arm/st/wb/stm32wb.dtsi:372 */
			counter {
				compatible = "st,stm32-counter"; /* in zephyr/dts/arm/st/wb/stm32wb.dtsi:373 */
				status = "disabled";             /* in zephyr/dts/arm/st/wb/stm32wb.dtsi:374 */
			};
		};

		/* node '/soc/timers@40014400' defined in zephyr/dts/arm/st/wb/stm32wb.dtsi:378 */
		timers16: timers@40014400 {
			compatible = "st,stm32-timers"; /* in zephyr/dts/arm/st/wb/stm32wb.dtsi:379 */
			reg = < 0x40014400 0x400 >;     /* in zephyr/dts/arm/st/wb/stm32wb.dtsi:380 */
			clocks = < &rcc 0x60 0x20000 >,
			         < &rcc 0xa 0xff >;     /* in zephyr/dts/arm/st/wb/stm32wb.dtsi:381 */
			resets = < &rctl 0x811 >;       /* in zephyr/dts/arm/st/wb/stm32wb.dtsi:383 */
			interrupts = < 0x19 0x0 >;      /* in zephyr/dts/arm/st/wb/stm32wb.dtsi:384 */
			interrupt-names = "global";     /* in zephyr/dts/arm/st/wb/stm32wb.dtsi:385 */
			st,prescaler = < 0x0 >;         /* in zephyr/dts/arm/st/wb/stm32wb.dtsi:386 */
			status = "disabled";            /* in zephyr/dts/arm/st/wb/stm32wb.dtsi:387 */

			/* node '/soc/timers@40014400/pwm' defined in zephyr/dts/arm/st/wb/stm32wb.dtsi:389 */
			pwm {
				compatible = "st,stm32-pwm"; /* in zephyr/dts/arm/st/wb/stm32wb.dtsi:390 */
				status = "disabled";         /* in zephyr/dts/arm/st/wb/stm32wb.dtsi:391 */
				#pwm-cells = < 0x3 >;        /* in zephyr/dts/arm/st/wb/stm32wb.dtsi:392 */
			};

			/* node '/soc/timers@40014400/counter' defined in zephyr/dts/arm/st/wb/stm32wb.dtsi:395 */
			counter {
				compatible = "st,stm32-counter"; /* in zephyr/dts/arm/st/wb/stm32wb.dtsi:396 */
				status = "disabled";             /* in zephyr/dts/arm/st/wb/stm32wb.dtsi:397 */
			};
		};

		/* node '/soc/timers@40014800' defined in zephyr/dts/arm/st/wb/stm32wb.dtsi:401 */
		timers17: timers@40014800 {
			compatible = "st,stm32-timers"; /* in zephyr/dts/arm/st/wb/stm32wb.dtsi:402 */
			reg = < 0x40014800 0x400 >;     /* in zephyr/dts/arm/st/wb/stm32wb.dtsi:403 */
			clocks = < &rcc 0x60 0x40000 >,
			         < &rcc 0xa 0xff >;     /* in zephyr/dts/arm/st/wb/stm32wb.dtsi:404 */
			resets = < &rctl 0x812 >;       /* in zephyr/dts/arm/st/wb/stm32wb.dtsi:406 */
			interrupts = < 0x1a 0x0 >;      /* in zephyr/dts/arm/st/wb/stm32wb.dtsi:407 */
			interrupt-names = "global";     /* in zephyr/dts/arm/st/wb/stm32wb.dtsi:408 */
			st,prescaler = < 0x0 >;         /* in zephyr/dts/arm/st/wb/stm32wb.dtsi:409 */
			status = "disabled";            /* in zephyr/dts/arm/st/wb/stm32wb.dtsi:410 */

			/* node '/soc/timers@40014800/pwm' defined in zephyr/dts/arm/st/wb/stm32wb.dtsi:412 */
			pwm {
				compatible = "st,stm32-pwm"; /* in zephyr/dts/arm/st/wb/stm32wb.dtsi:413 */
				status = "disabled";         /* in zephyr/dts/arm/st/wb/stm32wb.dtsi:414 */
				#pwm-cells = < 0x3 >;        /* in zephyr/dts/arm/st/wb/stm32wb.dtsi:415 */
			};

			/* node '/soc/timers@40014800/counter' defined in zephyr/dts/arm/st/wb/stm32wb.dtsi:418 */
			counter {
				compatible = "st,stm32-counter"; /* in zephyr/dts/arm/st/wb/stm32wb.dtsi:419 */
				status = "disabled";             /* in zephyr/dts/arm/st/wb/stm32wb.dtsi:420 */
			};
		};

		/* node '/soc/adc@50040000' defined in zephyr/dts/arm/st/wb/stm32wb.dtsi:424 */
		adc1: adc@50040000 {
			compatible = "st,stm32-adc";                                /* in zephyr/dts/arm/st/wb/stm32wb.dtsi:425 */
			reg = < 0x50040000 0x400 >;                                 /* in zephyr/dts/arm/st/wb/stm32wb.dtsi:426 */
			clocks = < &rcc 0x4c 0x2000 >;                              /* in zephyr/dts/arm/st/wb/stm32wb.dtsi:427 */
			clock-names = "adcx";                                       /* in zephyr/dts/arm/st/wb/stm32wb.dtsi:428 */
			interrupts = < 0x12 0x0 >;                                  /* in zephyr/dts/arm/st/wb/stm32wb.dtsi:429 */
			#io-channel-cells = < 0x1 >;                                /* in zephyr/dts/arm/st/wb/stm32wb.dtsi:430 */
			resolutions = < 0x60630c 0x51630c 0x42630c 0x33630c >;      /* in zephyr/dts/arm/st/wb/stm32wb.dtsi:431 */
			sampling-times = < 0x3 0x7 0xd 0x19 0x30 0x5d 0xf8 0x281 >; /* in zephyr/dts/arm/st/wb/stm32wb.dtsi:435 */
			st,adc-sequencer = "programmable";                          /* in zephyr/dts/arm/st/wb/stm32wb.dtsi:436 */
			st,adc-oversampler = "minimal";                             /* in zephyr/dts/arm/st/wb/stm32wb.dtsi:437 */
			st,adc-internal-regulator = "startup-sw-delay";             /* in zephyr/dts/arm/st/wb/stm32wb.dtsi:438 */
			st,adc-has-differential-support;                            /* in zephyr/dts/arm/st/wb/stm32wb.dtsi:439 */
			st,adc-has-deep-powerdown;                                  /* in zephyr/dts/arm/st/wb/stm32wb.dtsi:440 */
			pinctrl-0 = < &adc1_in3_pc2 &adc1_in5_pa0 >;                /* in zephyr/boards/st/nucleo_wb55rg/nucleo_wb55rg.dts:189 */
			pinctrl-names = "default";                                  /* in zephyr/boards/st/nucleo_wb55rg/nucleo_wb55rg.dts:190 */
			st,adc-clock-source = "SYNC";                               /* in zephyr/boards/st/nucleo_wb55rg/nucleo_wb55rg.dts:191 */
			st,adc-prescaler = < 0x4 >;                                 /* in zephyr/boards/st/nucleo_wb55rg/nucleo_wb55rg.dts:192 */
			status = "okay";                                            /* in zephyr/boards/st/nucleo_wb55rg/nucleo_wb55rg.dts:193 */
			phandle = < 0x1f >;                                         /* in zephyr/dts/arm/st/wb/stm32wb.dtsi:567 */
		};

		/* node '/soc/watchdog@40003000' defined in zephyr/dts/arm/st/wb/stm32wb.dtsi:444 */
		iwdg: watchdog@40003000 {
			compatible = "st,stm32-watchdog"; /* in zephyr/dts/arm/st/wb/stm32wb.dtsi:445 */
			reg = < 0x40003000 0x400 >;       /* in zephyr/dts/arm/st/wb/stm32wb.dtsi:446 */
			status = "okay";                  /* in zephyr/boards/st/nucleo_wb55rg/nucleo_wb55rg.dts:197 */
		};

		/* node '/soc/timers@40007c00' defined in zephyr/dts/arm/st/wb/stm32wb.dtsi:450 */
		lptim1: stm32_lp_tick_source: timers@40007c00 {
			compatible = "st,stm32-lptim";     /* in zephyr/dts/arm/st/wb/stm32wb.dtsi:451 */
			#address-cells = < 0x1 >;          /* in zephyr/dts/arm/st/wb/stm32wb.dtsi:453 */
			#size-cells = < 0x0 >;             /* in zephyr/dts/arm/st/wb/stm32wb.dtsi:454 */
			reg = < 0x40007c00 0x400 >;        /* in zephyr/dts/arm/st/wb/stm32wb.dtsi:455 */
			interrupts = < 0x2f 0x1 >;         /* in zephyr/dts/arm/st/wb/stm32wb.dtsi:456 */
			interrupt-names = "wakeup";        /* in zephyr/dts/arm/st/wb/stm32wb.dtsi:457 */
			clocks = < &rcc 0x58 0x80000000 >,
			         < &rcc 0x2 0x3320088 >;   /* in zephyr/boards/st/nucleo_wb55rg/nucleo_wb55rg.dts:201 */
			status = "okay";                   /* in zephyr/boards/st/nucleo_wb55rg/nucleo_wb55rg.dts:203 */
		};

		/* node '/soc/dma@40020000' defined in zephyr/dts/arm/st/wb/stm32wb.dtsi:461 */
		dma1: dma@40020000 {
			compatible = "st,stm32-dma-v2";                                             /* in zephyr/dts/arm/st/wb/stm32wb.dtsi:462 */
			#dma-cells = < 0x3 >;                                                       /* in zephyr/dts/arm/st/wb/stm32wb.dtsi:463 */
			reg = < 0x40020000 0x400 >;                                                 /* in zephyr/dts/arm/st/wb/stm32wb.dtsi:464 */
			interrupts = < 0xb 0x0 0xc 0x0 0xd 0x0 0xe 0x0 0xf 0x0 0x10 0x0 0x11 0x0 >; /* in zephyr/dts/arm/st/wb/stm32wb.dtsi:465 */
			clocks = < &rcc 0x48 0x1 >;                                                 /* in zephyr/dts/arm/st/wb/stm32wb.dtsi:466 */
			dma-requests = < 0x7 >;                                                     /* in zephyr/dts/arm/st/wb/stm32wb.dtsi:467 */
			dma-offset = < 0x0 >;                                                       /* in zephyr/dts/arm/st/wb/stm32wb.dtsi:468 */
			status = "disabled";                                                        /* in zephyr/dts/arm/st/wb/stm32wb.dtsi:469 */
		};

		/* node '/soc/dma@40020400' defined in zephyr/dts/arm/st/wb/stm32wb.dtsi:472 */
		dma2: dma@40020400 {
			compatible = "st,stm32-dma-v2";                                                  /* in zephyr/dts/arm/st/wb/stm32wb.dtsi:473 */
			#dma-cells = < 0x3 >;                                                            /* in zephyr/dts/arm/st/wb/stm32wb.dtsi:474 */
			reg = < 0x40020400 0x400 >;                                                      /* in zephyr/dts/arm/st/wb/stm32wb.dtsi:475 */
			interrupts = < 0x37 0x0 0x38 0x0 0x39 0x0 0x3a 0x0 0x3b 0x0 0x3c 0x0 0x3d 0x0 >; /* in zephyr/dts/arm/st/wb/stm32wb.dtsi:476 */
			clocks = < &rcc 0x48 0x2 >;                                                      /* in zephyr/dts/arm/st/wb/stm32wb.dtsi:477 */
			dma-requests = < 0x7 >;                                                          /* in zephyr/dts/arm/st/wb/stm32wb.dtsi:478 */
			dma-offset = < 0x7 >;                                                            /* in zephyr/dts/arm/st/wb/stm32wb.dtsi:479 */
			status = "disabled";                                                             /* in zephyr/dts/arm/st/wb/stm32wb.dtsi:480 */
		};

		/* node '/soc/dmamux@40020800' defined in zephyr/dts/arm/st/wb/stm32wb.dtsi:483 */
		dmamux1: dmamux@40020800 {
			compatible = "st,stm32-dmamux"; /* in zephyr/dts/arm/st/wb/stm32wb.dtsi:484 */
			#dma-cells = < 0x3 >;           /* in zephyr/dts/arm/st/wb/stm32wb.dtsi:485 */
			reg = < 0x40020800 0x400 >;     /* in zephyr/dts/arm/st/wb/stm32wb.dtsi:486 */
			interrupts = < 0x3e 0x0 >;      /* in zephyr/dts/arm/st/wb/stm32wb.dtsi:487 */
			clocks = < &rcc 0x48 0x4 >;     /* in zephyr/dts/arm/st/wb/stm32wb.dtsi:488 */
			dma-channels = < 0xe >;         /* in zephyr/dts/arm/st/wb/stm32wb.dtsi:489 */
			dma-generators = < 0x4 >;       /* in zephyr/dts/arm/st/wb/stm32wb.dtsi:490 */
			dma-requests = < 0x24 >;        /* in zephyr/dts/arm/st/wb/stm32wb.dtsi:491 */
			status = "disabled";            /* in zephyr/dts/arm/st/wb/stm32wb.dtsi:492 */
		};

		/* node '/soc/usb@40006800' defined in zephyr/dts/arm/st/wb/stm32wb.dtsi:495 */
		usb: zephyr_udc0: usb@40006800 {
			compatible = "st,stm32-usb";               /* in zephyr/dts/arm/st/wb/stm32wb.dtsi:496 */
			reg = < 0x40006800 0x400 >;                /* in zephyr/dts/arm/st/wb/stm32wb.dtsi:497 */
			interrupts = < 0x14 0x0 >,
			             < 0x13 0x0 >;                 /* in zephyr/dts/arm/st/wb/stm32wb.dtsi:498 */
			interrupt-names = "usb",
			                  "usbhp";                 /* in zephyr/dts/arm/st/wb/stm32wb.dtsi:499 */
			num-bidir-endpoints = < 0x8 >;             /* in zephyr/dts/arm/st/wb/stm32wb.dtsi:500 */
			ram-size = < 0x400 >;                      /* in zephyr/dts/arm/st/wb/stm32wb.dtsi:501 */
			maximum-speed = "full-speed";              /* in zephyr/dts/arm/st/wb/stm32wb.dtsi:502 */
			phys = < &usb_fs_phy >;                    /* in zephyr/dts/arm/st/wb/stm32wb.dtsi:503 */
			clocks = < &rcc 0x58 0x4000000 >,
			         < &rcc 0x5 0x3a0088 >;            /* in zephyr/dts/arm/st/wb/stm32wb.dtsi:504 */
			status = "okay";                           /* in zephyr/boards/st/nucleo_wb55rg/nucleo_wb55rg.dts:207 */
			pinctrl-0 = < &usb_dm_pa11 &usb_dp_pa12 >; /* in zephyr/boards/st/nucleo_wb55rg/nucleo_wb55rg.dts:208 */
			pinctrl-names = "default";                 /* in zephyr/boards/st/nucleo_wb55rg/nucleo_wb55rg.dts:209 */
		};

		/* node '/soc/spi@a0001000' defined in zephyr/dts/arm/st/wb/stm32wb.dtsi:509 */
		quadspi: spi@a0001000 {
			compatible = "st,stm32-qspi";    /* in zephyr/dts/arm/st/wb/stm32wb.dtsi:510 */
			#address-cells = < 0x1 >;        /* in zephyr/dts/arm/st/wb/stm32wb.dtsi:511 */
			#size-cells = < 0x0 >;           /* in zephyr/dts/arm/st/wb/stm32wb.dtsi:512 */
			reg = < 0xa0001000 0x400 >,
			      < 0x90000000 0x10000000 >; /* in zephyr/dts/arm/st/wb/stm32wb.dtsi:513 */
			interrupts = < 0x32 0x0 >;       /* in zephyr/dts/arm/st/wb/stm32wb.dtsi:514 */
			clocks = < &rcc 0x50 0x100 >;    /* in zephyr/dts/arm/st/wb/stm32wb.dtsi:515 */
			status = "disabled";             /* in zephyr/dts/arm/st/wb/stm32wb.dtsi:516 */
		};

		/* node '/soc/rng@58001000' defined in zephyr/dts/arm/st/wb/stm32wb.dtsi:519 */
		rng: rng@58001000 {
			compatible = "st,stm32-rng";    /* in zephyr/dts/arm/st/wb/stm32wb.dtsi:520 */
			reg = < 0x58001000 0x400 >;     /* in zephyr/dts/arm/st/wb/stm32wb.dtsi:521 */
			interrupts = < 0x35 0x0 >;      /* in zephyr/dts/arm/st/wb/stm32wb.dtsi:522 */
			clocks = < &rcc 0x50 0x40000 >; /* in zephyr/dts/arm/st/wb/stm32wb.dtsi:523 */
			status = "okay";                /* in zephyr/boards/st/nucleo_wb55rg/nucleo_wb55rg.dts:213 */
		};

		/* node '/soc/aes@50060000' defined in zephyr/dts/arm/st/wb/stm32wb.dtsi:527 */
		aes1: aes@50060000 {
			compatible = "st,stm32-aes";    /* in zephyr/dts/arm/st/wb/stm32wb.dtsi:528 */
			reg = < 0x50060000 0x400 >;     /* in zephyr/dts/arm/st/wb/stm32wb.dtsi:529 */
			clocks = < &rcc 0x4c 0x10000 >; /* in zephyr/dts/arm/st/wb/stm32wb.dtsi:530 */
			resets = < &rctl 0x590 >;       /* in zephyr/dts/arm/st/wb/stm32wb.dtsi:531 */
			interrupts = < 0x33 0x0 >;      /* in zephyr/dts/arm/st/wb/stm32wb.dtsi:532 */
			status = "okay";                /* in zephyr/boards/st/nucleo_wb55rg/nucleo_wb55rg.dts:217 */
		};

		/* node '/soc/power@58000400' defined in zephyr/dts/arm/st/wb/stm32wb.dtsi:536 */
		pwr: power@58000400 {
			compatible = "st,stm32-pwr"; /* in zephyr/dts/arm/st/wb/stm32wb.dtsi:537 */
			reg = < 0x58000400 0x400 >;  /* in zephyr/dts/arm/st/wb/stm32wb.dtsi:538 */
			status = "disabled";         /* in zephyr/dts/arm/st/wb/stm32wb.dtsi:539 */
			wkup-pins-nb = < 0x5 >;      /* in zephyr/dts/arm/st/wb/stm32wb.dtsi:541 */
			wkup-pins-pol;               /* in zephyr/dts/arm/st/wb/stm32wb.dtsi:542 */
			wkup-pins-pupd;              /* in zephyr/dts/arm/st/wb/stm32wb.dtsi:543 */
			#address-cells = < 0x1 >;    /* in zephyr/dts/arm/st/wb/stm32wb.dtsi:545 */
			#size-cells = < 0x0 >;       /* in zephyr/dts/arm/st/wb/stm32wb.dtsi:546 */

			/* node '/soc/power@58000400/wkup-pin@1' defined in zephyr/dts/arm/st/wb/stm32wb.dtsi:548 */
			wkup-pin@1 {
				reg = < 0x1 >;                   /* in zephyr/dts/arm/st/wb/stm32wb.dtsi:549 */
				wkup-gpios = < &gpioa 0x0 0x1 >; /* in zephyr/dts/arm/st/wb/stm32wb.dtsi:550 */
			};

			/* node '/soc/power@58000400/wkup-pin@4' defined in zephyr/dts/arm/st/wb/stm32wb.dtsi:553 */
			wkup-pin@4 {
				reg = < 0x4 >;                   /* in zephyr/dts/arm/st/wb/stm32wb.dtsi:554 */
				wkup-gpios = < &gpioa 0x2 0x1 >; /* in zephyr/dts/arm/st/wb/stm32wb.dtsi:555 */
			};

			/* node '/soc/power@58000400/wkup-pin@2' defined in zephyr/dts/arm/st/wb/stm32wb55Xg.dtsi:24 */
			wkup-pin@2 {
				reg = < 0x2 >;                   /* in zephyr/dts/arm/st/wb/stm32wb55Xg.dtsi:25 */
				wkup-gpios = < &gpioc 0xd 0x1 >; /* in zephyr/dts/arm/st/wb/stm32wb55Xg.dtsi:26 */
			};

			/* node '/soc/power@58000400/wkup-pin@3' defined in zephyr/dts/arm/st/wb/stm32wb55Xg.dtsi:29 */
			wkup-pin@3 {
				reg = < 0x3 >;                   /* in zephyr/dts/arm/st/wb/stm32wb55Xg.dtsi:30 */
				wkup-gpios = < &gpioc 0xc 0x1 >; /* in zephyr/dts/arm/st/wb/stm32wb55Xg.dtsi:31 */
			};

			/* node '/soc/power@58000400/wkup-pin@5' defined in zephyr/dts/arm/st/wb/stm32wb55Xg.dtsi:34 */
			wkup-pin@5 {
				reg = < 0x5 >;                   /* in zephyr/dts/arm/st/wb/stm32wb55Xg.dtsi:35 */
				wkup-gpios = < &gpioc 0x5 0x1 >; /* in zephyr/dts/arm/st/wb/stm32wb55Xg.dtsi:36 */
			};
		};
	};

	/* node '/cpus' defined in zephyr/dts/arm/st/wb/stm32wb.dtsi:30 */
	cpus {
		#address-cells = < 0x1 >; /* in zephyr/dts/arm/st/wb/stm32wb.dtsi:31 */
		#size-cells = < 0x0 >;    /* in zephyr/dts/arm/st/wb/stm32wb.dtsi:32 */

		/* node '/cpus/cpu@0' defined in zephyr/dts/arm/st/wb/stm32wb.dtsi:34 */
		cpu0: cpu@0 {
			device_type = "cpu";                         /* in zephyr/dts/arm/st/wb/stm32wb.dtsi:35 */
			compatible = "arm,cortex-m4f";               /* in zephyr/dts/arm/st/wb/stm32wb.dtsi:36 */
			reg = < 0x0 >;                               /* in zephyr/dts/arm/st/wb/stm32wb.dtsi:37 */
			cpu-power-states = < &stop0 &stop1 &stop2 >; /* in zephyr/dts/arm/st/wb/stm32wb.dtsi:38 */
		};

		/* node '/cpus/power-states' defined in zephyr/dts/arm/st/wb/stm32wb.dtsi:41 */
		power-states {

			/* node '/cpus/power-states/state0' defined in zephyr/dts/arm/st/wb/stm32wb.dtsi:42 */
			stop0: state0 {
				compatible = "zephyr,power-state";    /* in zephyr/dts/arm/st/wb/stm32wb.dtsi:43 */
				power-state-name = "suspend-to-idle"; /* in zephyr/dts/arm/st/wb/stm32wb.dtsi:44 */
				substate-id = < 0x1 >;                /* in zephyr/dts/arm/st/wb/stm32wb.dtsi:45 */
				min-residency-us = < 0x64 >;          /* in zephyr/dts/arm/st/wb/stm32wb.dtsi:46 */
				phandle = < 0x1c >;                   /* in zephyr/dts/arm/st/wb/stm32wb.dtsi:38 */
			};

			/* node '/cpus/power-states/state1' defined in zephyr/dts/arm/st/wb/stm32wb.dtsi:49 */
			stop1: state1 {
				compatible = "zephyr,power-state";    /* in zephyr/dts/arm/st/wb/stm32wb.dtsi:50 */
				power-state-name = "suspend-to-idle"; /* in zephyr/dts/arm/st/wb/stm32wb.dtsi:51 */
				substate-id = < 0x2 >;                /* in zephyr/dts/arm/st/wb/stm32wb.dtsi:52 */
				min-residency-us = < 0x1f4 >;         /* in zephyr/dts/arm/st/wb/stm32wb.dtsi:53 */
				phandle = < 0x1d >;                   /* in zephyr/dts/arm/st/wb/stm32wb.dtsi:38 */
			};

			/* node '/cpus/power-states/state2' defined in zephyr/dts/arm/st/wb/stm32wb.dtsi:56 */
			stop2: state2 {
				compatible = "zephyr,power-state";    /* in zephyr/dts/arm/st/wb/stm32wb.dtsi:57 */
				power-state-name = "suspend-to-idle"; /* in zephyr/dts/arm/st/wb/stm32wb.dtsi:58 */
				substate-id = < 0x3 >;                /* in zephyr/dts/arm/st/wb/stm32wb.dtsi:59 */
				min-residency-us = < 0x384 >;         /* in zephyr/dts/arm/st/wb/stm32wb.dtsi:60 */
				phandle = < 0x1e >;                   /* in zephyr/dts/arm/st/wb/stm32wb.dtsi:38 */
			};
		};
	};

	/* node '/memory@20000000' defined in zephyr/dts/arm/st/wb/stm32wb.dtsi:65 */
	sram0: memory@20000000 {
		compatible = "zephyr,memory-region",
		             "mmio-sram";            /* in zephyr/dts/arm/st/wb/stm32wb.dtsi:66 */
		zephyr,memory-region = "SRAM0";      /* in zephyr/dts/arm/st/wb/stm32wb.dtsi:67 */
		reg = < 0x20000000 0x30000 >;        /* in zephyr/dts/arm/st/wb/stm32wb55Xg.dtsi:11 */
	};

	/* node '/memory@20030000' defined in zephyr/dts/arm/st/wb/stm32wb.dtsi:70 */
	sram1: memory@20030000 {
		compatible = "zephyr,memory-region",
		             "mmio-sram";            /* in zephyr/dts/arm/st/wb/stm32wb.dtsi:71 */
		reg = < 0x20030000 0x2800 >;         /* in zephyr/dts/arm/st/wb/stm32wb.dtsi:72 */
		zephyr,memory-region = "SRAM1";      /* in zephyr/dts/arm/st/wb/stm32wb.dtsi:73 */
	};

	/* node '/memory@20038000' defined in zephyr/dts/arm/st/wb/stm32wb.dtsi:76 */
	sram2: memory@20038000 {
		compatible = "zephyr,memory-region",
		             "mmio-sram";            /* in zephyr/dts/arm/st/wb/stm32wb.dtsi:77 */
		reg = < 0x20038000 0x5000 >;         /* in zephyr/dts/arm/st/wb/stm32wb.dtsi:78 */
		zephyr,memory-region = "SRAM2";      /* in zephyr/dts/arm/st/wb/stm32wb.dtsi:79 */
	};

	/* node '/clocks' defined in zephyr/dts/arm/st/wb/stm32wb.dtsi:82 */
	clocks {

		/* node '/clocks/clk-hse' defined in zephyr/dts/arm/st/wb/stm32wb.dtsi:83 */
		clk_hse: clk-hse {
			#clock-cells = < 0x0 >;          /* in zephyr/dts/arm/st/wb/stm32wb.dtsi:84 */
			compatible = "fixed-clock";      /* in zephyr/dts/arm/st/wb/stm32wb.dtsi:85 */
			clock-frequency = < 0x1e84800 >; /* in zephyr/dts/arm/st/wb/stm32wb.dtsi:87 */
			status = "okay";                 /* in zephyr/boards/st/nucleo_wb55rg/nucleo_wb55rg.dts:93 */
			phandle = < 0x3 >;               /* in zephyr/boards/st/nucleo_wb55rg/nucleo_wb55rg.dts:111 */
		};

		/* node '/clocks/clk-hsi' defined in zephyr/dts/arm/st/wb/stm32wb.dtsi:91 */
		clk_hsi: clk-hsi {
			#clock-cells = < 0x0 >;         /* in zephyr/dts/arm/st/wb/stm32wb.dtsi:92 */
			compatible = "fixed-clock";     /* in zephyr/dts/arm/st/wb/stm32wb.dtsi:93 */
			clock-frequency = < 0xf42400 >; /* in zephyr/dts/arm/st/wb/stm32wb.dtsi:94 */
			status = "disabled";            /* in zephyr/dts/arm/st/wb/stm32wb.dtsi:95 */
		};

		/* node '/clocks/clk-hsi48' defined in zephyr/dts/arm/st/wb/stm32wb.dtsi:98 */
		clk_hsi48: clk-hsi48 {
			#clock-cells = < 0x0 >;          /* in zephyr/dts/arm/st/wb/stm32wb.dtsi:99 */
			compatible = "fixed-clock";      /* in zephyr/dts/arm/st/wb/stm32wb.dtsi:100 */
			clock-frequency = < 0x2dc6c00 >; /* in zephyr/dts/arm/st/wb/stm32wb.dtsi:101 */
			status = "okay";                 /* in zephyr/boards/st/nucleo_wb55rg/nucleo_wb55rg.dts:101 */
		};

		/* node '/clocks/clk-msi' defined in zephyr/dts/arm/st/wb/stm32wb.dtsi:105 */
		clk_msi: clk-msi {
			#clock-cells = < 0x0 >;            /* in zephyr/dts/arm/st/wb/stm32wb.dtsi:106 */
			compatible = "st,stm32-msi-clock"; /* in zephyr/dts/arm/st/wb/stm32wb.dtsi:107 */
			msi-range = < 0x6 >;               /* in zephyr/dts/arm/st/wb/stm32wb.dtsi:108 */
			status = "disabled";               /* in zephyr/dts/arm/st/wb/stm32wb.dtsi:109 */
		};

		/* node '/clocks/clk-lse' defined in zephyr/dts/arm/st/wb/stm32wb.dtsi:112 */
		clk_lse: clk-lse {
			#clock-cells = < 0x0 >;            /* in zephyr/dts/arm/st/wb/stm32wb.dtsi:113 */
			compatible = "st,stm32-lse-clock"; /* in zephyr/dts/arm/st/wb/stm32wb.dtsi:114 */
			clock-frequency = < 0x8000 >;      /* in zephyr/dts/arm/st/wb/stm32wb.dtsi:115 */
			driving-capability = < 0x0 >;      /* in zephyr/dts/arm/st/wb/stm32wb.dtsi:116 */
			status = "okay";                   /* in zephyr/boards/st/nucleo_wb55rg/nucleo_wb55rg.dts:97 */
		};

		/* node '/clocks/clk-lsi1' defined in zephyr/dts/arm/st/wb/stm32wb.dtsi:120 */
		clk_lsi1: clk-lsi1 {
			#clock-cells = < 0x0 >;       /* in zephyr/dts/arm/st/wb/stm32wb.dtsi:121 */
			compatible = "fixed-clock";   /* in zephyr/dts/arm/st/wb/stm32wb.dtsi:122 */
			clock-frequency = < 0x7d00 >; /* in zephyr/dts/arm/st/wb/stm32wb.dtsi:123 */
			status = "okay";              /* in zephyr/boards/st/nucleo_wb55rg/nucleo_wb55rg.dts:89 */
		};

		/* node '/clocks/clk-lsi2' defined in zephyr/dts/arm/st/wb/stm32wb.dtsi:127 */
		clk_lsi2: clk-lsi2 {
			#clock-cells = < 0x0 >;       /* in zephyr/dts/arm/st/wb/stm32wb.dtsi:128 */
			compatible = "fixed-clock";   /* in zephyr/dts/arm/st/wb/stm32wb.dtsi:129 */
			clock-frequency = < 0x7d00 >; /* in zephyr/dts/arm/st/wb/stm32wb.dtsi:130 */
			status = "disabled";          /* in zephyr/dts/arm/st/wb/stm32wb.dtsi:131 */
		};

		/* node '/clocks/pll' defined in zephyr/dts/arm/st/wb/stm32wb.dtsi:134 */
		pll: pll {
			#clock-cells = < 0x0 >;              /* in zephyr/dts/arm/st/wb/stm32wb.dtsi:135 */
			compatible = "st,stm32wb-pll-clock"; /* in zephyr/dts/arm/st/wb/stm32wb.dtsi:136 */
			status = "disabled";                 /* in zephyr/dts/arm/st/wb/stm32wb.dtsi:137 */
		};

		/* node '/clocks/clk48' defined in zephyr/dts/arm/st/wb/stm32wb.dtsi:140 */
		clk48: clk48 {
			#clock-cells = < 0x0 >;            /* in zephyr/dts/arm/st/wb/stm32wb.dtsi:141 */
			compatible = "st,stm32-clock-mux"; /* in zephyr/dts/arm/st/wb/stm32wb.dtsi:142 */
			status = "disabled";               /* in zephyr/dts/arm/st/wb/stm32wb.dtsi:143 */
			clocks = < &rcc 0x5 0x3a0088 >;    /* in zephyr/boards/st/nucleo_wb55rg/nucleo_wb55rg.dts:107 */
		};
	};

	/* node '/dietemp' defined in zephyr/dts/arm/st/wb/stm32wb.dtsi:560 */
	die_temp: dietemp {
		compatible = "st,stm32-temp-cal"; /* in zephyr/dts/arm/st/wb/stm32wb.dtsi:561 */
		ts-cal1-addr = < 0x1fff75a8 >;    /* in zephyr/dts/arm/st/wb/stm32wb.dtsi:562 */
		ts-cal2-addr = < 0x1fff75ca >;    /* in zephyr/dts/arm/st/wb/stm32wb.dtsi:563 */
		ts-cal1-temp = < 0x1e >;          /* in zephyr/dts/arm/st/wb/stm32wb.dtsi:564 */
		ts-cal2-temp = < 0x82 >;          /* in zephyr/dts/arm/st/wb/stm32wb.dtsi:565 */
		ts-cal-vrefanalog = < 0xbb8 >;    /* in zephyr/dts/arm/st/wb/stm32wb.dtsi:566 */
		io-channels = < &adc1 0x11 >;     /* in zephyr/dts/arm/st/wb/stm32wb.dtsi:567 */
		status = "okay";                  /* in zephyr/boards/st/nucleo_wb55rg/nucleo_wb55rg.dts:85 */
	};

	/* node '/vref' defined in zephyr/dts/arm/st/wb/stm32wb.dtsi:571 */
	vref: vref {
		compatible = "st,stm32-vref";      /* in zephyr/dts/arm/st/wb/stm32wb.dtsi:572 */
		vrefint-cal-addr = < 0x1fff75aa >; /* in zephyr/dts/arm/st/wb/stm32wb.dtsi:573 */
		vrefint-cal-mv = < 0xe10 >;        /* in zephyr/dts/arm/st/wb/stm32wb.dtsi:574 */
		io-channels = < &adc1 0x0 >;       /* in zephyr/dts/arm/st/wb/stm32wb.dtsi:575 */
		status = "okay";                   /* in zephyr/boards/st/nucleo_wb55rg/nucleo_wb55rg.dts:261 */
	};

	/* node '/vbat' defined in zephyr/dts/arm/st/wb/stm32wb.dtsi:579 */
	vbat: vbat {
		compatible = "st,stm32-vbat"; /* in zephyr/dts/arm/st/wb/stm32wb.dtsi:580 */
		ratio = < 0x3 >;              /* in zephyr/dts/arm/st/wb/stm32wb.dtsi:581 */
		io-channels = < &adc1 0x12 >; /* in zephyr/dts/arm/st/wb/stm32wb.dtsi:582 */
		status = "okay";              /* in zephyr/boards/st/nucleo_wb55rg/nucleo_wb55rg.dts:265 */
	};

	/* node '/usbphy' defined in zephyr/dts/arm/st/wb/stm32wb.dtsi:586 */
	usb_fs_phy: usbphy {
		compatible = "usb-nop-xceiv"; /* in zephyr/dts/arm/st/wb/stm32wb.dtsi:587 */
		#phy-cells = < 0x0 >;         /* in zephyr/dts/arm/st/wb/stm32wb.dtsi:588 */
		phandle = < 0x17 >;           /* in zephyr/dts/arm/st/wb/stm32wb.dtsi:503 */
	};

	/* node '/ble_rf' defined in zephyr/dts/arm/st/wb/stm32wb.dtsi:591 */
	ble_rf: ble_rf {
		compatible = "st,stm32wb-rf";    /* in zephyr/dts/arm/st/wb/stm32wb.dtsi:592 */
		clocks = < &rcc 0x50 0x100000 >,
		         < &rcc 0x2 0x12e0094 >; /* in zephyr/dts/arm/st/wb/stm32wb.dtsi:593 */
	};

	/* node '/smbus1' defined in zephyr/dts/arm/st/wb/stm32wb.dtsi:597 */
	smbus1: smbus1 {
		compatible = "st,stm32-smbus"; /* in zephyr/dts/arm/st/wb/stm32wb.dtsi:598 */
		#address-cells = < 0x1 >;      /* in zephyr/dts/arm/st/wb/stm32wb.dtsi:599 */
		#size-cells = < 0x0 >;         /* in zephyr/dts/arm/st/wb/stm32wb.dtsi:600 */
		i2c = < &i2c1 >;               /* in zephyr/dts/arm/st/wb/stm32wb.dtsi:601 */
		status = "disabled";           /* in zephyr/dts/arm/st/wb/stm32wb.dtsi:602 */
	};

	/* node '/smbus3' defined in zephyr/dts/arm/st/wb/stm32wb.dtsi:605 */
	smbus3: smbus3 {
		compatible = "st,stm32-smbus"; /* in zephyr/dts/arm/st/wb/stm32wb.dtsi:606 */
		#address-cells = < 0x1 >;      /* in zephyr/dts/arm/st/wb/stm32wb.dtsi:607 */
		#size-cells = < 0x0 >;         /* in zephyr/dts/arm/st/wb/stm32wb.dtsi:608 */
		i2c = < &i2c3 >;               /* in zephyr/dts/arm/st/wb/stm32wb.dtsi:609 */
		status = "disabled";           /* in zephyr/dts/arm/st/wb/stm32wb.dtsi:610 */
	};

	/* node '/connector' defined in zephyr/boards/st/nucleo_wb55rg/arduino_r3_connector.dtsi:10 */
	arduino_header: connector {
		compatible = "arduino-header-r3";          /* in zephyr/boards/st/nucleo_wb55rg/arduino_r3_connector.dtsi:11 */
		#gpio-cells = < 0x2 >;                     /* in zephyr/boards/st/nucleo_wb55rg/arduino_r3_connector.dtsi:12 */
		gpio-map-mask = < 0xffffffff 0xffffffc0 >; /* in zephyr/boards/st/nucleo_wb55rg/arduino_r3_connector.dtsi:13 */
		gpio-map-pass-thru = < 0x0 0x3f >;         /* in zephyr/boards/st/nucleo_wb55rg/arduino_r3_connector.dtsi:14 */
		gpio-map = < 0x0 0x0 &gpioc 0x0 0x0 >,
		           < 0x1 0x0 &gpioc 0x1 0x0 >,
		           < 0x2 0x0 &gpioa 0x1 0x0 >,
		           < 0x3 0x0 &gpioa 0x0 0x0 >,
		           < 0x4 0x0 &gpioc 0x3 0x0 >,
		           < 0x5 0x0 &gpioc 0x2 0x0 >,
		           < 0x6 0x0 &gpioa 0x3 0x0 >,
		           < 0x7 0x0 &gpioa 0x2 0x0 >,
		           < 0x8 0x0 &gpioc 0x6 0x0 >,
		           < 0x9 0x0 &gpioa 0xa 0x0 >,
		           < 0xa 0x0 &gpioc 0xa 0x0 >,
		           < 0xb 0x0 &gpioa 0xf 0x0 >,
		           < 0xc 0x0 &gpioa 0x8 0x0 >,
		           < 0xd 0x0 &gpioc 0xd 0x0 >,
		           < 0xe 0x0 &gpioc 0xc 0x0 >,
		           < 0xf 0x0 &gpioa 0x9 0x0 >,
		           < 0x10 0x0 &gpioa 0x4 0x0 >,
		           < 0x11 0x0 &gpioa 0x7 0x0 >,
		           < 0x12 0x0 &gpioa 0x6 0x0 >,
		           < 0x13 0x0 &gpioa 0x5 0x0 >,
		           < 0x14 0x0 &gpiob 0x9 0x0 >,
		           < 0x15 0x0 &gpiob 0x8 0x0 >;    /* in zephyr/boards/st/nucleo_wb55rg/arduino_r3_connector.dtsi:15 */
	};

	/* node '/leds' defined in zephyr/boards/st/nucleo_wb55rg/nucleo_wb55rg.dts:27 */
	leds: leds {
		compatible = "gpio-leds"; /* in zephyr/boards/st/nucleo_wb55rg/nucleo_wb55rg.dts:28 */

		/* node '/leds/led_0' defined in zephyr/boards/st/nucleo_wb55rg/nucleo_wb55rg.dts:30 */
		blue_led_1: led_0 {
			gpios = < &gpiob 0x5 0x0 >; /* in zephyr/boards/st/nucleo_wb55rg/nucleo_wb55rg.dts:31 */
			label = "User LED1";        /* in zephyr/boards/st/nucleo_wb55rg/nucleo_wb55rg.dts:32 */
		};

		/* node '/leds/led_1' defined in zephyr/boards/st/nucleo_wb55rg/nucleo_wb55rg.dts:35 */
		green_led_2: led_1 {
			gpios = < &gpiob 0x0 0x0 >; /* in zephyr/boards/st/nucleo_wb55rg/nucleo_wb55rg.dts:36 */
			label = "User LED2";        /* in zephyr/boards/st/nucleo_wb55rg/nucleo_wb55rg.dts:37 */
		};

		/* node '/leds/led_2' defined in zephyr/boards/st/nucleo_wb55rg/nucleo_wb55rg.dts:40 */
		red_led_3: led_2 {
			gpios = < &gpiob 0x1 0x0 >; /* in zephyr/boards/st/nucleo_wb55rg/nucleo_wb55rg.dts:41 */
			label = "User LED3";        /* in zephyr/boards/st/nucleo_wb55rg/nucleo_wb55rg.dts:42 */
		};
	};

	/* node '/gpio_keys' defined in zephyr/boards/st/nucleo_wb55rg/nucleo_wb55rg.dts:46 */
	gpio_keys {
		compatible = "gpio-keys"; /* in zephyr/boards/st/nucleo_wb55rg/nucleo_wb55rg.dts:47 */

		/* node '/gpio_keys/button_0' defined in zephyr/boards/st/nucleo_wb55rg/nucleo_wb55rg.dts:49 */
		user_button_1: button_0 {
			label = "SW1";               /* in zephyr/boards/st/nucleo_wb55rg/nucleo_wb55rg.dts:50 */
			gpios = < &gpioc 0x4 0x11 >; /* in zephyr/boards/st/nucleo_wb55rg/nucleo_wb55rg.dts:51 */
			zephyr,code = < 0xb >;       /* in zephyr/boards/st/nucleo_wb55rg/nucleo_wb55rg.dts:52 */
		};

		/* node '/gpio_keys/button_1' defined in zephyr/boards/st/nucleo_wb55rg/nucleo_wb55rg.dts:55 */
		user_button_2: button_1 {
			label = "SW2";               /* in zephyr/boards/st/nucleo_wb55rg/nucleo_wb55rg.dts:56 */
			gpios = < &gpiod 0x0 0x11 >; /* in zephyr/boards/st/nucleo_wb55rg/nucleo_wb55rg.dts:57 */
			zephyr,code = < 0x2 >;       /* in zephyr/boards/st/nucleo_wb55rg/nucleo_wb55rg.dts:58 */
		};

		/* node '/gpio_keys/button_2' defined in zephyr/boards/st/nucleo_wb55rg/nucleo_wb55rg.dts:61 */
		user_button_3: button_2 {
			label = "SW3";               /* in zephyr/boards/st/nucleo_wb55rg/nucleo_wb55rg.dts:62 */
			gpios = < &gpiod 0x1 0x11 >; /* in zephyr/boards/st/nucleo_wb55rg/nucleo_wb55rg.dts:63 */
			zephyr,code = < 0x3 >;       /* in zephyr/boards/st/nucleo_wb55rg/nucleo_wb55rg.dts:64 */
		};
	};
};
